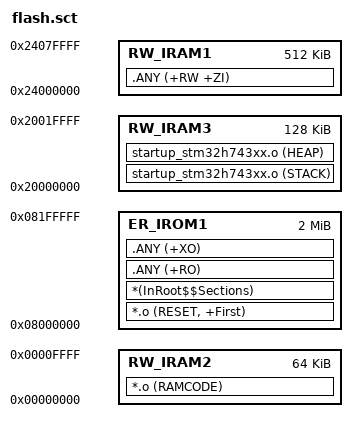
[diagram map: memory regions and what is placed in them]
; *************************************************************
; *** Scatter-Loading Description File generated by uVision ***
; *************************************************************




LR_IROM1 0x08000000 0x00200000  {    ; load region size_region
  ER_IROM1 0x08000000 0x00200000  {  ; load address = execution address
   *.o (RESET, +First)
   *(InRoot$$Sections)
   .ANY (+RO)
   .ANY (+XO)
  }
  RW_IRAM1 0x24000000 0x00080000  {  ; RW data
   .ANY (+RW +ZI)
   
;   *(AXI_SRAM)
  }

  RW_IRAM2 0x00000000 0x00010000  {  ; 
;   *(ITCM)  
    *.o (RAMCODE)
  }
  RW_IRAM3 0x20000000 0x00020000  {  ; 
;   *(DTCM)
   startup_stm32h743xx.o (STACK)
   startup_stm32h743xx.o (HEAP)
  }

;  RW_IRAM4 0xC0000000 0x02000000  {  ; 
;    *(SDRAM)
;  }

;  RW_IRAM5 0x30000000 0x00020000  {  ; 
;   *(AHB_SRAM1)
;  }

;  RW_IRAM6 0x30020000 0x00020000  {  ;
;   *(AHB_SRAM2)
;  }

;  RW_IRAM7 0x30040000 0x00008000  {  ;
;   *(AHB_SRAM3)
;  }

;  RW_IRAM8 0x38000000 0x00010000  {  ;
;   *(AHB_SRAM4)
;  }
}


